VERSION ""

NS_ :

BS_:

BU_: XXX

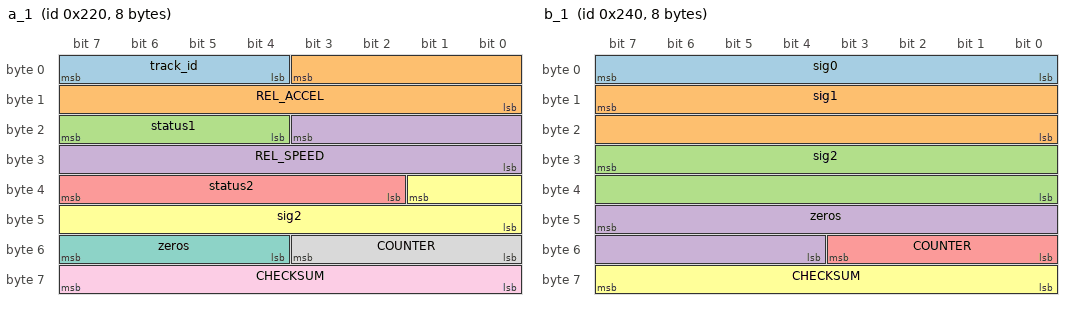
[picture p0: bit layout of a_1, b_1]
BO_ 544 a_1: 8 XXX
 SG_ track_id : 7|4@0+ (1,0) [0|15] "" XXX
 SG_ REL_ACCEL : 3|12@0+ (1,0) [0|31] "" XXX
 SG_ status1 : 23|4@0+ (1,0) [0|15] "" XXX
 SG_ REL_SPEED : 19|12@0+ (1,0) [0|65535] "" XXX
 SG_ status2 : 39|6@0+ (1,0) [0|15] "" XXX
 SG_ sig2 : 33|10@0+ (1,0) [0|255] "" XXX
 SG_ zeros : 55|4@0+ (1,0) [0|15] "" XXX
 SG_ COUNTER : 51|4@0+ (1,0) [0|15] "" XXX
 SG_ CHECKSUM : 63|8@0+ (1,0) [0|255] "" XXX

BO_ 576 b_1: 8 XXX
 SG_ sig0 : 7|8@0+ (1,0) [0|255] "" XXX
 SG_ sig1 : 15|16@0+ (1,0) [0|65535] "" XXX
 SG_ sig2 : 31|16@0+ (1,0) [0|255] "" XXX
 SG_ zeros : 47|12@0+ (1,0) [0|255] "" XXX
 SG_ COUNTER : 51|4@0+ (1,0) [0|15] "" XXX
 SG_ CHECKSUM : 63|8@0+ (1,0) [0|255] "" XXX

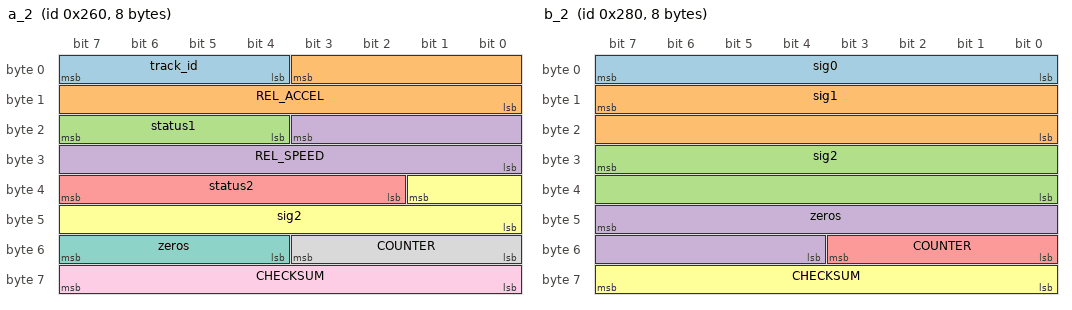
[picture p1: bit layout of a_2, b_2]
BO_ 608 a_2: 8 XXX
 SG_ track_id : 7|4@0+ (1,0) [0|15] "" XXX
 SG_ REL_ACCEL : 3|12@0+ (1,0) [0|31] "" XXX
 SG_ status1 : 23|4@0+ (1,0) [0|15] "" XXX
 SG_ REL_SPEED : 19|12@0+ (1,0) [0|65535] "" XXX
 SG_ status2 : 39|6@0+ (1,0) [0|15] "" XXX
 SG_ sig2 : 33|10@0+ (1,0) [0|255] "" XXX
 SG_ zeros : 55|4@0+ (1,0) [0|15] "" XXX
 SG_ COUNTER : 51|4@0+ (1,0) [0|15] "" XXX
 SG_ CHECKSUM : 63|8@0+ (1,0) [0|255] "" XXX

BO_ 640 b_2: 8 XXX
 SG_ sig0 : 7|8@0+ (1,0) [0|255] "" XXX
 SG_ sig1 : 15|16@0+ (1,0) [0|65535] "" XXX
 SG_ sig2 : 31|16@0+ (1,0) [0|255] "" XXX
 SG_ zeros : 47|12@0+ (1,0) [0|255] "" XXX
 SG_ COUNTER : 51|4@0+ (1,0) [0|15] "" XXX
 SG_ CHECKSUM : 63|8@0+ (1,0) [0|255] "" XXX

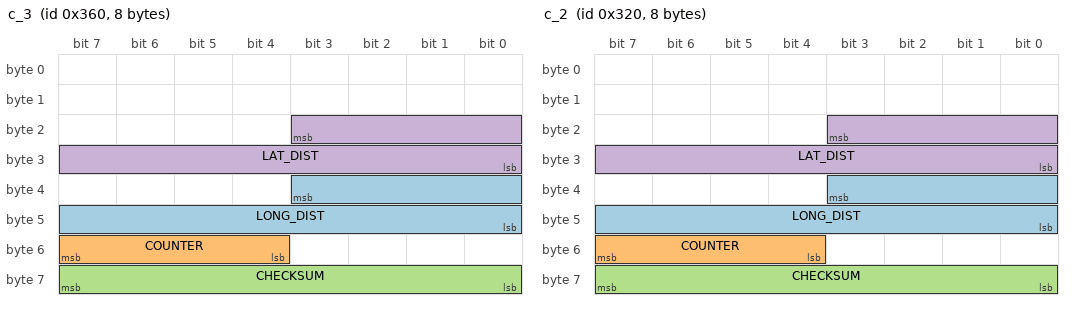
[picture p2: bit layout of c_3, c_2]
BO_ 864 c_3: 8 XXX
 SG_ LONG_DIST : 35|12@0+ (0,0) [0|255] "m" XXX
 SG_ COUNTER : 55|4@0+ (1,0) [0|15] "" XXX
 SG_ CHECKSUM : 63|8@0+ (1,0) [0|255] "" XXX
 SG_ LAT_DIST : 19|12@0+ (0.005,-1000) [0|2047] "m" XXX

BO_ 800 c_2: 8 XXX
 SG_ LONG_DIST : 35|12@0+ (0,0) [0|255] "m" XXX
 SG_ COUNTER : 55|4@0+ (1,0) [0|15] "" XXX
 SG_ CHECKSUM : 63|8@0+ (1,0) [0|255] "" XXX
 SG_ LAT_DIST : 19|12@0+ (0.005,-1000) [0|2047] "m" XXX

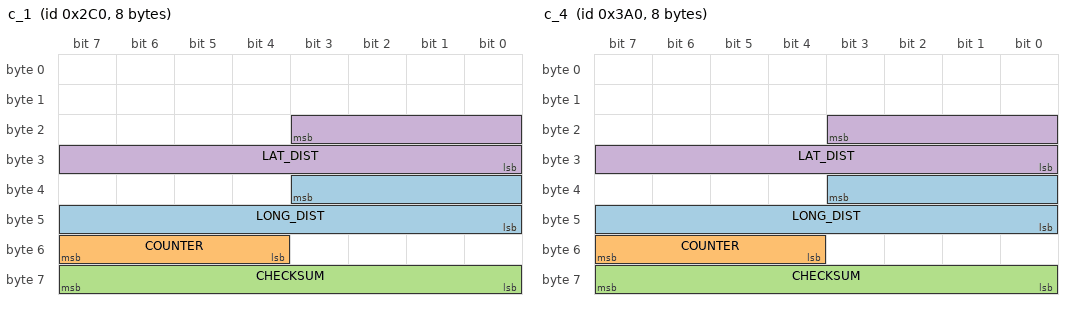
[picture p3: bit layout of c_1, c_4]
BO_ 704 c_1: 8 XXX
 SG_ LONG_DIST : 35|12@0+ (0,0) [0|255] "m" XXX
 SG_ COUNTER : 55|4@0+ (1,0) [0|15] "" XXX
 SG_ CHECKSUM : 63|8@0+ (1,0) [0|255] "" XXX
 SG_ LAT_DIST : 19|12@0+ (0.005,-1000) [0|2047] "m" XXX

BO_ 928 c_4: 8 XXX
 SG_ LONG_DIST : 35|12@0+ (0,0) [0|255] "m" XXX
 SG_ COUNTER : 55|4@0+ (1,0) [0|15] "" XXX
 SG_ CHECKSUM : 63|8@0+ (1,0) [0|255] "" XXX
 SG_ LAT_DIST : 19|12@0+ (0.005,-1000) [0|2047] "m" XXX

BO_ 672 d_1: 8 XXX
 SG_ REL_SPEED : 17|10@0+ (0.2857,-146.278) [0|1023] "m/s" XXX

BO_ 768 d_2: 8 XXX
 SG_ REL_SPEED : 17|10@0+ (0.2857,-146.278) [0|1023] "m/s" XXX

BO_ 832 d_3: 8 XXX
 SG_ REL_SPEED : 17|10@0+ (0.2857,-146.278) [0|1023] "m/s" XXX

BO_ 896 d_4: 8 XXX
 SG_ REL_SPEED : 17|10@0+ (0.2857,-146.278) [0|1023] "m/s" XXX

CM_ SG_ 544 track_id "for message a_1 track_id is always 1, similar for other messages and track_id";
CM_ SG_ 544 REL_ACCEL "perhaps REL_ACCEL because it responds faster and before REL_SPEED";
CM_ SG_ 544 sig2 "perhaps distance to object. LONG_DIST or REL_ACCEL or REL_SPEED";
CM_ SG_ 576 zeros "not always zero, sometimes has value when another car changes lanes";
CM_ SG_ 706 LAT_DIST "positive is to the right, negative is to the left";
CM_ SG_ 864 LAT_DIST "positive is to the right, negative to the left";
